VERSION ""

NS_ :

BS_:

BU_:

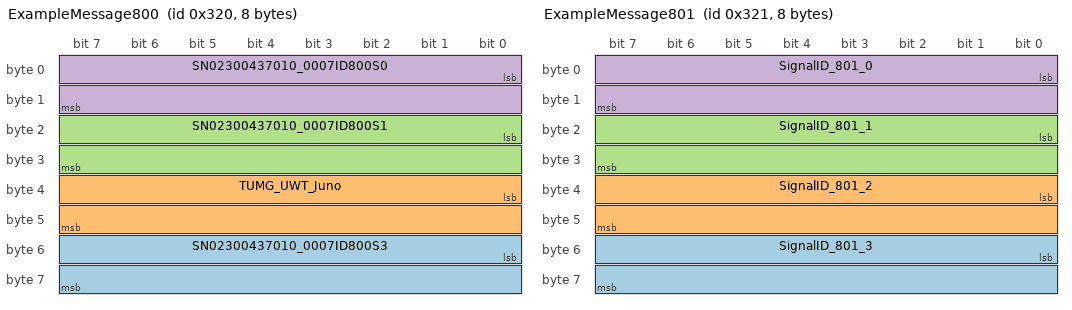
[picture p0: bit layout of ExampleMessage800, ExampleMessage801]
BO_ 800 ExampleMessage800: 8 Vector__XXX
 SG_ SN02300437010_0007ID800S3 : 48|16@1+ (1,0) [-3000|3000] "digit" Vector__XXX
 SG_ TUMG_UWT_Juno : 32|16@1- (0.01,0) [-3000|3000] "°C" Vector__XXX
 SG_ SN02300437010_0007ID800S1 : 16|16@1+ (1,0) [-3000|3000] "digit" Vector__XXX
 SG_ SN02300437010_0007ID800S0 : 0|16@1+ (1,0) [-3000|3000] "digit" Vector__XXX

BO_ 801 ExampleMessage801: 8 Vector__XXX
 SG_ SignalID_801_3 : 48|16@1+ (1,0) [-3000|3000] "digit" Vector__XXX
 SG_ SignalID_801_2 : 32|16@1+ (1,0) [-3000|3000] "digit" Vector__XXX
 SG_ SignalID_801_1 : 16|16@1+ (1,0) [-3000|3000] "digit" Vector__XXX
 SG_ SignalID_801_0 : 0|16@1+ (1,0) [-3000|3000] "digit" Vector__XXX

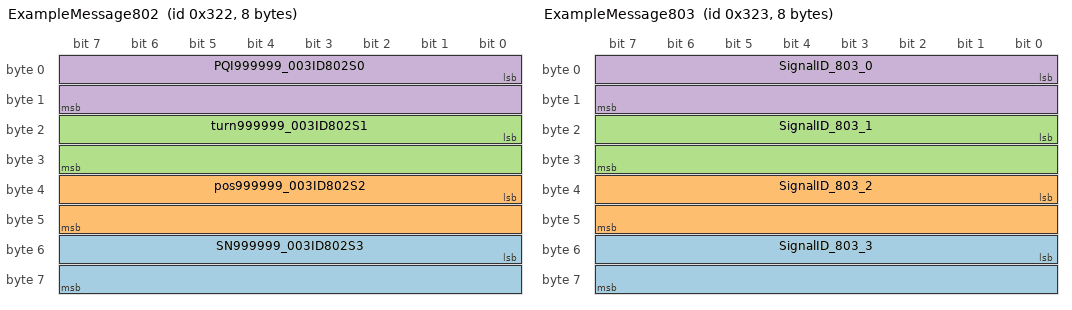
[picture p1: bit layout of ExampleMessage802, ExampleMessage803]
BO_ 802 ExampleMessage802: 8 Vector__XXX
 SG_ SN999999_003ID802S3 : 48|16@1+ (1,0) [-3000|3000] "digit" Vector__XXX
 SG_ pos999999_003ID802S2 : 32|16@1+ (0.0054932478828107,0) [-3000|3000] "°" Vector__XXX
 SG_ turn999999_003ID802S1 : 16|16@1+ (1,0) [-3000|3000] "dom" Vector__XXX
 SG_ PQI999999_003ID802S0 : 0|16@1+ (1,0) [-3000|3000] "PQI" Vector__XXX

BO_ 803 ExampleMessage803: 8 Vector__XXX
 SG_ SignalID_803_3 : 48|16@1+ (1,0) [-3000|3000] "digit" Vector__XXX
 SG_ SignalID_803_2 : 32|16@1+ (1,0) [-3000|3000] "digit" Vector__XXX
 SG_ SignalID_803_1 : 16|16@1+ (1,0) [-3000|3000] "digit" Vector__XXX
 SG_ SignalID_803_0 : 0|16@1+ (1,0) [-3000|3000] "digit" Vector__XXX

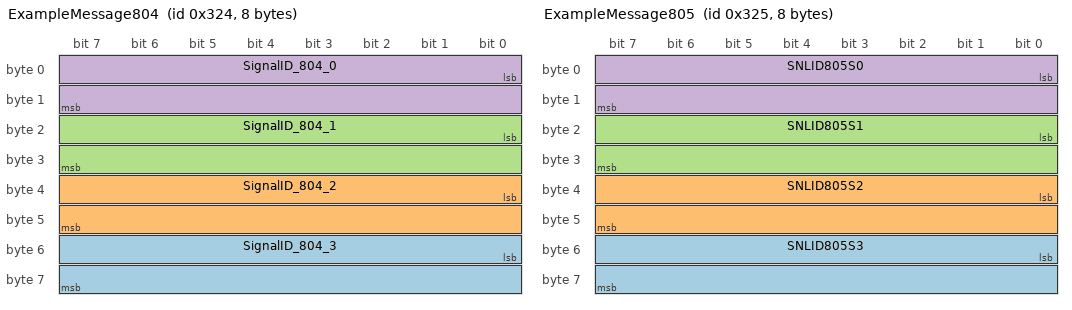
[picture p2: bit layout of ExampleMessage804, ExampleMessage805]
BO_ 804 ExampleMessage804: 8 Vector__XXX
 SG_ SignalID_804_3 : 48|16@1+ (1,0) [-3000|3000] "digit" Vector__XXX
 SG_ SignalID_804_2 : 32|16@1+ (1,0) [-3000|3000] "digit" Vector__XXX
 SG_ SignalID_804_1 : 16|16@1+ (1,0) [-3000|3000] "digit" Vector__XXX
 SG_ SignalID_804_0 : 0|16@1+ (1,0) [-3000|3000] "digit" Vector__XXX

BO_ 805 ExampleMessage805: 8 Vector__XXX
 SG_ SNLID805S3 : 48|16@1+ (1,0) [-3000|3000] "digit" Vector__XXX
 SG_ SNLID805S2 : 32|16@1+ (1,0) [-3000|3000] "digit" Vector__XXX
 SG_ SNLID805S1 : 16|16@1+ (1,0) [-3000|3000] "digit" Vector__XXX
 SG_ SNLID805S0 : 0|16@1+ (1,0) [-3000|3000] "digit" Vector__XXX

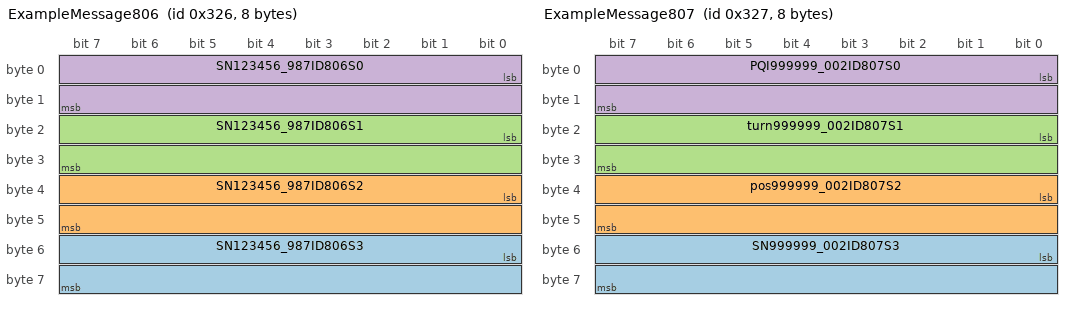
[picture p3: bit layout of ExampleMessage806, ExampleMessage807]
BO_ 806 ExampleMessage806: 8 Vector__XXX
 SG_ SN123456_987ID806S3 : 48|16@1+ (1,0) [-3000|3000] "digit" Vector__XXX
 SG_ SN123456_987ID806S2 : 32|16@1+ (1,0) [-3000|3000] "digit" Vector__XXX
 SG_ SN123456_987ID806S1 : 16|16@1+ (1,0) [-3000|3000] "digit" Vector__XXX
 SG_ SN123456_987ID806S0 : 0|16@1+ (1,0) [-3000|3000] "digit" Vector__XXX

BO_ 807 ExampleMessage807: 8 Vector__XXX
 SG_ SN999999_002ID807S3 : 48|16@1+ (1,0) [-3000|3000] "digit" Vector__XXX
 SG_ pos999999_002ID807S2 : 32|16@1+ (0.0054932478828107,0) [-3000|3000] "°" Vector__XXX
 SG_ turn999999_002ID807S1 : 16|16@1+ (1,0) [-3000|3000] "dom" Vector__XXX
 SG_ PQI999999_002ID807S0 : 0|16@1+ (1,0) [-3000|3000] "PQI" Vector__XXX

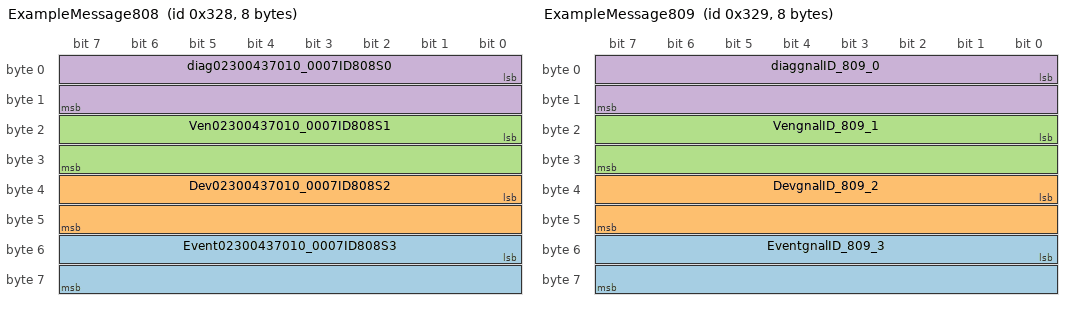
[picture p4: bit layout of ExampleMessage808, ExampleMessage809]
BO_ 808 ExampleMessage808: 8 Vector__XXX
 SG_ Event02300437010_0007ID808S3 : 48|16@1+ (1,0) [-3000|3000] "Event" Vector__XXX
 SG_ Dev02300437010_0007ID808S2 : 32|16@1+ (1,0) [-3000|3000] "Dev" Vector__XXX
 SG_ Ven02300437010_0007ID808S1 : 16|16@1+ (1,0) [-3000|3000] "Vendor" Vector__XXX
 SG_ diag02300437010_0007ID808S0 : 0|16@1+ (1,0) [-3000|3000] "PQI" Vector__XXX

BO_ 809 ExampleMessage809: 8 Vector__XXX
 SG_ EventgnalID_809_3 : 48|16@1+ (1,0) [-3000|3000] "Event" Vector__XXX
 SG_ DevgnalID_809_2 : 32|16@1+ (1,0) [-3000|3000] "Dev" Vector__XXX
 SG_ VengnalID_809_1 : 16|16@1+ (1,0) [-3000|3000] "Vendor" Vector__XXX
 SG_ diaggnalID_809_0 : 0|16@1+ (1,0) [-3000|3000] "PQI" Vector__XXX

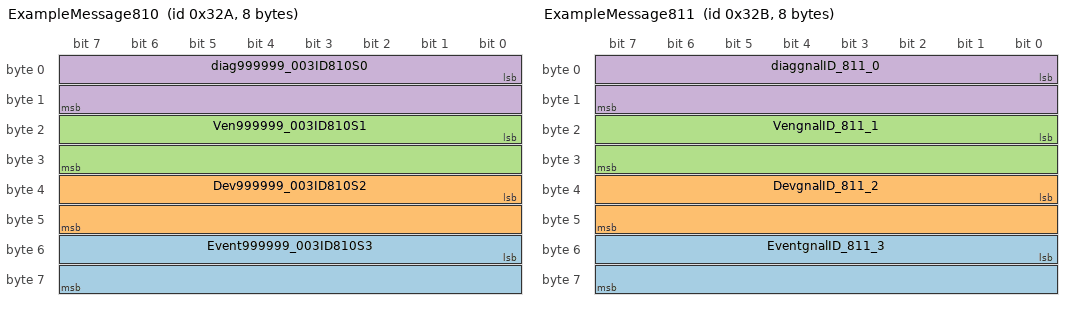
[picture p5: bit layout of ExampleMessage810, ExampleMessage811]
BO_ 810 ExampleMessage810: 8 Vector__XXX
 SG_ Event999999_003ID810S3 : 48|16@1+ (1,0) [-3000|3000] "Event" Vector__XXX
 SG_ Dev999999_003ID810S2 : 32|16@1+ (1,0) [-3000|3000] "Dev" Vector__XXX
 SG_ Ven999999_003ID810S1 : 16|16@1+ (1,0) [-3000|3000] "Vendor" Vector__XXX
 SG_ diag999999_003ID810S0 : 0|16@1+ (1,0) [-3000|3000] "PQI" Vector__XXX

BO_ 811 ExampleMessage811: 8 Vector__XXX
 SG_ EventgnalID_811_3 : 48|16@1+ (1,0) [-3000|3000] "Event" Vector__XXX
 SG_ DevgnalID_811_2 : 32|16@1+ (1,0) [-3000|3000] "Dev" Vector__XXX
 SG_ VengnalID_811_1 : 16|16@1+ (1,0) [-3000|3000] "Vendor" Vector__XXX
 SG_ diaggnalID_811_0 : 0|16@1+ (1,0) [-3000|3000] "PQI" Vector__XXX

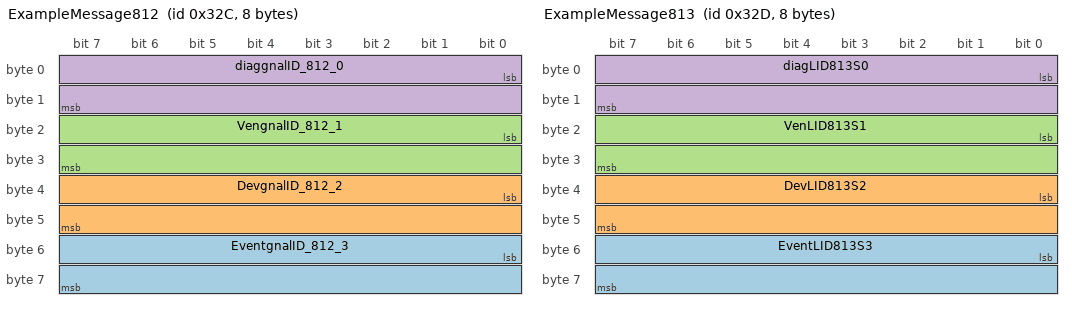
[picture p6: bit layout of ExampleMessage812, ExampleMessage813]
BO_ 812 ExampleMessage812: 8 Vector__XXX
 SG_ EventgnalID_812_3 : 48|16@1+ (1,0) [-3000|3000] "Event" Vector__XXX
 SG_ DevgnalID_812_2 : 32|16@1+ (1,0) [-3000|3000] "Dev" Vector__XXX
 SG_ VengnalID_812_1 : 16|16@1+ (1,0) [-3000|3000] "Vendor" Vector__XXX
 SG_ diaggnalID_812_0 : 0|16@1+ (1,0) [-3000|3000] "PQI" Vector__XXX

BO_ 813 ExampleMessage813: 8 Vector__XXX
 SG_ EventLID813S3 : 48|16@1+ (1,0) [-3000|3000] "Event" Vector__XXX
 SG_ DevLID813S2 : 32|16@1+ (1,0) [-3000|3000] "Dev" Vector__XXX
 SG_ VenLID813S1 : 16|16@1+ (1,0) [-3000|3000] "Vendor" Vector__XXX
 SG_ diagLID813S0 : 0|16@1+ (1,0) [-3000|3000] "PQI" Vector__XXX

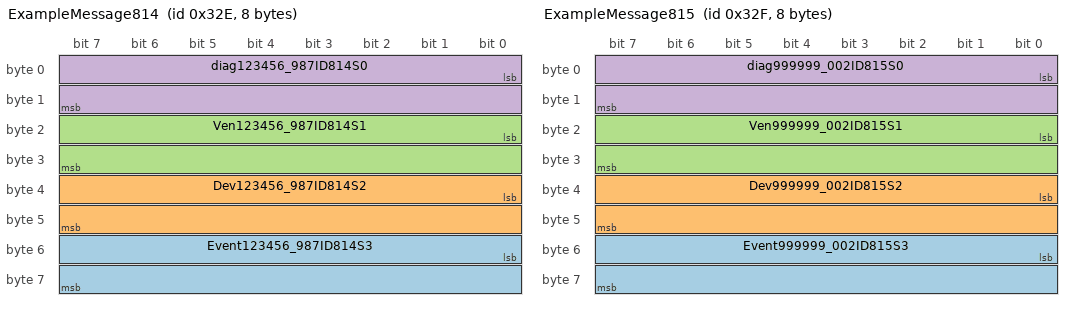
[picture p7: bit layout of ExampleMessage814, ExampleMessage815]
BO_ 814 ExampleMessage814: 8 Vector__XXX
 SG_ Event123456_987ID814S3 : 48|16@1+ (1,0) [-3000|3000] "Event" Vector__XXX
 SG_ Dev123456_987ID814S2 : 32|16@1+ (1,0) [-3000|3000] "Dev" Vector__XXX
 SG_ Ven123456_987ID814S1 : 16|16@1+ (1,0) [-3000|3000] "Vendor" Vector__XXX
 SG_ diag123456_987ID814S0 : 0|16@1+ (1,0) [-3000|3000] "PQI" Vector__XXX

BO_ 815 ExampleMessage815: 8 Vector__XXX
 SG_ Event999999_002ID815S3 : 48|16@1+ (1,0) [-3000|3000] "Event" Vector__XXX
 SG_ Dev999999_002ID815S2 : 32|16@1+ (1,0) [-3000|3000] "Dev" Vector__XXX
 SG_ Ven999999_002ID815S1 : 16|16@1+ (1,0) [-3000|3000] "Vendor" Vector__XXX
 SG_ diag999999_002ID815S0 : 0|16@1+ (1,0) [-3000|3000] "PQI" Vector__XXX

CM_ SG_ 800 SN02300437010_0007ID800S3 "SN02300437010_0007";
CM_ SG_ 800 TUMG_UWT_Juno "SN02300437010_0007";
CM_ SG_ 800 SN02300437010_0007ID800S1 "SN02300437010_0007";
CM_ SG_ 800 SN02300437010_0007ID800S0 "SN02300437010_0007";
CM_ SG_ 802 SN999999_003ID802S3 "SN999999_003";
CM_ SG_ 802 pos999999_003ID802S2 "SN999999_003";
CM_ SG_ 802 turn999999_003ID802S1 "SN999999_003";
CM_ SG_ 802 PQI999999_003ID802S0 "SN999999_003";
CM_ SG_ 805 SNLID805S3 "SNL";
CM_ SG_ 805 SNLID805S2 "SNL";
CM_ SG_ 805 SNLID805S1 "SNL";
CM_ SG_ 805 SNLID805S0 "SNL";
CM_ SG_ 806 SN123456_987ID806S3 "SN123456_987";
CM_ SG_ 806 SN123456_987ID806S2 "SN123456_987";
CM_ SG_ 806 SN123456_987ID806S1 "SN123456_987";
CM_ SG_ 806 SN123456_987ID806S0 "SN123456_987";
CM_ SG_ 807 SN999999_002ID807S3 "SN999999_002";
CM_ SG_ 807 pos999999_002ID807S2 "SN999999_002";
CM_ SG_ 807 turn999999_002ID807S1 "SN999999_002";
CM_ SG_ 807 PQI999999_002ID807S0 "SN999999_002";
CM_ SG_ 808 Event02300437010_0007ID808S3 "SN02300437010_0007";
CM_ SG_ 808 Dev02300437010_0007ID808S2 "SN02300437010_0007";
CM_ SG_ 808 Ven02300437010_0007ID808S1 "SN02300437010_0007";
CM_ SG_ 808 diag02300437010_0007ID808S0 "SN02300437010_0007";
CM_ SG_ 810 Event999999_003ID810S3 "SN999999_003";
CM_ SG_ 810 Dev999999_003ID810S2 "SN999999_003";
CM_ SG_ 810 Ven999999_003ID810S1 "SN999999_003";
CM_ SG_ 810 diag999999_003ID810S0 "SN999999_003";
CM_ SG_ 813 EventLID813S3 "SNL";
CM_ SG_ 813 DevLID813S2 "SNL";
CM_ SG_ 813 VenLID813S1 "SNL";
CM_ SG_ 813 diagLID813S0 "SNL";
CM_ SG_ 814 Event123456_987ID814S3 "SN123456_987";
CM_ SG_ 814 Dev123456_987ID814S2 "SN123456_987";
CM_ SG_ 814 Ven123456_987ID814S1 "SN123456_987";
CM_ SG_ 814 diag123456_987ID814S0 "SN123456_987";
CM_ SG_ 815 Event999999_002ID815S3 "SN999999_002";
CM_ SG_ 815 Dev999999_002ID815S2 "SN999999_002";
CM_ SG_ 815 Ven999999_002ID815S1 "SN999999_002";
CM_ SG_ 815 diag999999_002ID815S0 "SN999999_002";
